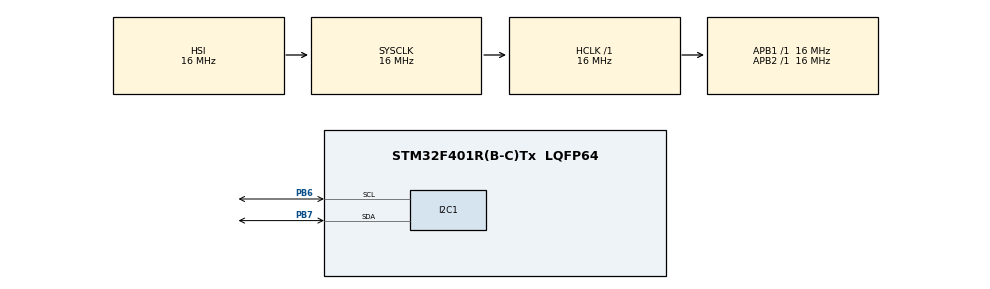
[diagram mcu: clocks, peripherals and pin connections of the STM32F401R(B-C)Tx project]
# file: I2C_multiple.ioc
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I2C1.OwnAddress=12
Mcu.Family=STM32F4
Mcu.Name=STM32F401R(B-C)Tx
Mcu.Package=LQFP64
NVIC.I2C1_ER_IRQn=true\:0\:0\:false\:false\:true\:true\:true\:true
NVIC.I2C1_EV_IRQn=true\:0\:0\:false\:false\:true\:true\:true\:true
NVIC.PriorityGroup=NVIC_PRIORITYGROUP_4
PB6.Mode=I2C
PB6.Signal=I2C1_SCL
PB7.Mode=I2C
PB7.Signal=I2C1_SDA
PH0\ -\ OSC_IN.Mode=HSE-External-Oscillator
PH0\ -\ OSC_IN.Signal=RCC_OSC_IN
PH1\ -\ OSC_OUT.Mode=HSE-External-Oscillator
PH1\ -\ OSC_OUT.Signal=RCC_OSC_OUT
ProjectManager.HeapSize=0x200
ProjectManager.StackSize=0x400
ProjectManager.TargetToolchain=STM32CubeIDE
RCC.AHBFreq_Value=16000000
RCC.APB1Freq_Value=16000000
RCC.APB2Freq_Value=16000000
RCC.CortexFreq_Value=16000000
RCC.HSE_VALUE=25000000
RCC.HSI_VALUE=16000000
RCC.LSE_VALUE=32768
RCC.SYSCLKFreq_VALUE=16000000
RCC.VCOOutputFreq_Value=192000000
board=custom

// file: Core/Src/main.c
/* USER CODE BEGIN Header */
/**
  ******************************************************************************
  * @file           : main.c
  * @brief          : Main program body
  ******************************************************************************
  * @attention
  *
  * Copyright (c) 2024 STMicroelectronics.
  * All rights reserved.
  *
  * This software is licensed under terms that can be found in the LICENSE file
  * in the root directory of this software component.
  * If no LICENSE file comes with this software, it is provided AS-IS.
  *
  ******************************************************************************
  */
/* USER CODE END Header */
#include "main.h"

I2C_HandleTypeDef hi2c1;

/* USER CODE BEGIN PV */
uint8_t size=6;
uint8_t Recieved_Data[6];
uint8_t Incr_Data[6];

/* USER CODE END PV */

void SystemClock_Config(void);
static void MX_GPIO_Init(void);
static void MX_I2C1_Init(void);
/* USER CODE BEGIN PFP */
void HAL_I2C_SlaveRxCpltCallback(I2C_HandleTypeDef *hi2c);
void HAL_I2C_ListenCpltCallback(I2C_HandleTypeDef *hi2c);
void HAL_I2C_AddrCallback(I2C_HandleTypeDef *hi2c, uint8_t TransferDirection, uint16_t AddrMatchCode);
void HAL_I2C_ErrorCallback(I2C_HandleTypeDef *hi2c);
void Index0_incr(uint8_t Data1);
void Index1_incr(uint8_t Data2);
void Index2_incr(uint8_t Data3);
void Index3_incr(uint8_t Data4);
void Index4_incr(uint8_t Data5);
void Index5_incr(uint8_t Data6);
/* USER CODE END PFP */

/* USER CODE BEGIN 0 */
void HAL_I2C_ListenCpltCallback(I2C_HandleTypeDef *hi2c)
{
	HAL_I2C_EnableListen_IT(hi2c);
	// it made to listen again to make the communication continuously
}

void HAL_I2C_AddrCallback(I2C_HandleTypeDef *hi2c, uint8_t TransferDirection, uint16_t AddrMatchCode)
//function called when slave address matches with master requirement
{
	if(TransferDirection == I2C_DIRECTION_TRANSMIT)
//transaction direction decides whether the master requested data or sent data to slave
	{
		HAL_I2C_Slave_Seq_Receive_IT(hi2c,Recieved_Data,size,I2C_FIRST_AND_LAST_FRAME);
		//recieve data from master and interrupt flag raised once done
	}
	else{
		Error_Handler();
	}
}
//function called once slave recieve is complete
void HAL_I2C_SlaveRxCpltCallback(I2C_HandleTypeDef *hi2c)
{
	Index0_incr(Recieved_Data[0]);//calling the functions to increment,giving the recieved data as parameter with appropriate index
	Index1_incr(Recieved_Data[1]);
	Index2_incr(Recieved_Data[2]);
	Index3_incr(Recieved_Data[3]);
	Index4_incr(Recieved_Data[4]);
	Index5_incr(Recieved_Data[5]);
}

void Index0_incr(uint8_t Data)// function definitons to increment the recieved value
{
	Incr_Data[0]=Data+1;
}
void Index1_incr(uint8_t Data)
{
	Incr_Data[1]=Data+1;
}
void Index2_incr(uint8_t Data)
{
	Incr_Data[2]=Data+1;
}
void Index3_incr(uint8_t Data)
{
	Incr_Data[3]=Data+1;
}
void Index4_incr(uint8_t Data)
{
	Incr_Data[4]=Data+1;
}
void Index5_incr(uint8_t Data)
{
	Incr_Data[5]=Data+1;
}

//this function is called when error happens while listening process
void HAL_I2C_ErrorCallback(I2C_HandleTypeDef *hi2c)
{
	HAL_I2C_EnableListen_IT(hi2c);
}

/* USER CODE END 0 */

int main(void)
{

  /* MCU Configuration--------------------------------------------------------*/

  /* Reset of all peripherals, Initializes the Flash interface and the Systick. */
  HAL_Init();

  /* Configure the system clock */
  SystemClock_Config();

  /* Initialize all configured peripherals */
  MX_GPIO_Init();
  MX_I2C1_Init();
  /* USER CODE BEGIN 2 */
  if(HAL_I2C_EnableListen_IT(&hi2c1) != HAL_OK)
//Enabling the I2C listen_interrupt for master recognition
  {
	  Error_Handler();
  }
  /* USER CODE END 2 */

  /* Infinite loop */
  while (1)
  {

  }
}

void SystemClock_Config(void)
{
  RCC_OscInitTypeDef RCC_OscInitStruct = {0};
  RCC_ClkInitTypeDef RCC_ClkInitStruct = {0};

  /** Configure the main internal regulator output voltage
  */
  __HAL_RCC_PWR_CLK_ENABLE();
  __HAL_PWR_VOLTAGESCALING_CONFIG(PWR_REGULATOR_VOLTAGE_SCALE2);

  /** Initializes the RCC Oscillators according to the specified parameters
  * in the RCC_OscInitTypeDef structure.
  */
  RCC_OscInitStruct.OscillatorType = RCC_OSCILLATORTYPE_HSI;
  RCC_OscInitStruct.HSIState = RCC_HSI_ON;
  RCC_OscInitStruct.HSICalibrationValue = RCC_HSICALIBRATION_DEFAULT;
  RCC_OscInitStruct.PLL.PLLState = RCC_PLL_NONE;
  if (HAL_RCC_OscConfig(&RCC_OscInitStruct) != HAL_OK)
  {
    Error_Handler();
  }

  /** Initializes the CPU, AHB and APB buses clocks
  */
  RCC_ClkInitStruct.ClockType = RCC_CLOCKTYPE_HCLK|RCC_CLOCKTYPE_SYSCLK
                              |RCC_CLOCKTYPE_PCLK1|RCC_CLOCKTYPE_PCLK2;
  RCC_ClkInitStruct.SYSCLKSource = RCC_SYSCLKSOURCE_HSI;
  RCC_ClkInitStruct.AHBCLKDivider = RCC_SYSCLK_DIV1;
  RCC_ClkInitStruct.APB1CLKDivider = RCC_HCLK_DIV1;
  RCC_ClkInitStruct.APB2CLKDivider = RCC_HCLK_DIV1;

  if (HAL_RCC_ClockConfig(&RCC_ClkInitStruct, FLASH_LATENCY_0) != HAL_OK)
  {
    Error_Handler();
  }
}

static void MX_I2C1_Init(void)
{

  hi2c1.Instance = I2C1;
  hi2c1.Init.ClockSpeed = 100000;
  hi2c1.Init.DutyCycle = I2C_DUTYCYCLE_2;
  hi2c1.Init.OwnAddress1 = 24;
  hi2c1.Init.AddressingMode = I2C_ADDRESSINGMODE_7BIT;
  hi2c1.Init.DualAddressMode = I2C_DUALADDRESS_DISABLE;
  hi2c1.Init.OwnAddress2 = 0;
  hi2c1.Init.GeneralCallMode = I2C_GENERALCALL_DISABLE;
  hi2c1.Init.NoStretchMode = I2C_NOSTRETCH_DISABLE;
  if (HAL_I2C_Init(&hi2c1) != HAL_OK)
  {
    Error_Handler();
  }

}

static void MX_GPIO_Init(void)
{

  /* GPIO Ports Clock Enable */
  __HAL_RCC_GPIOH_CLK_ENABLE();
  __HAL_RCC_GPIOB_CLK_ENABLE();

}

void Error_Handler(void)
{
  __disable_irq();
  while (1)
  {
  }
}
